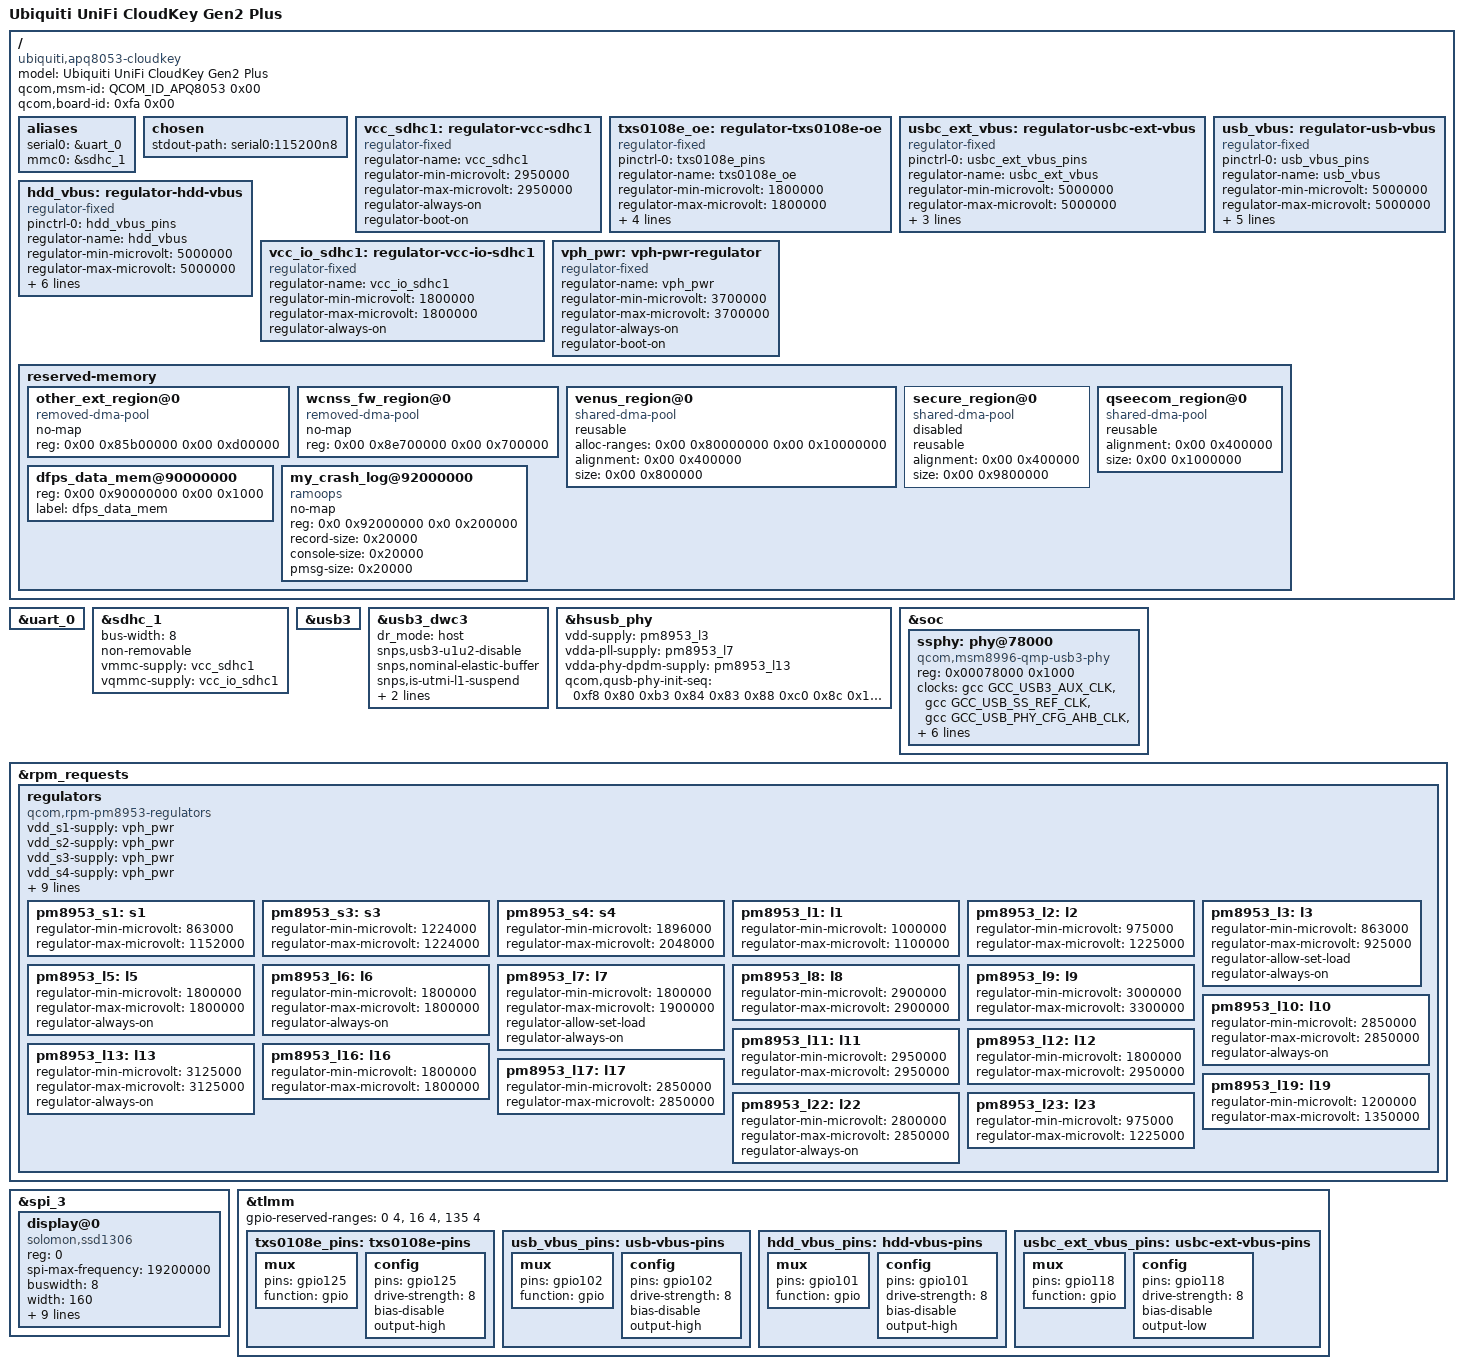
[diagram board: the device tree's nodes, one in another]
// SPDX-License-Identifier: BSD-3-Clause
/dts-v1/;

#include <dt-bindings/arm/qcom,ids.h>
#include "msm8953.dtsi"
#include "pm8953.dtsi"
#include <dt-bindings/gpio/gpio.h>

/ {
	model = "Ubiquiti UniFi CloudKey Gen2 Plus";
	compatible = "ubiquiti,apq8053-cloudkey", "qcom,apq8053-mtp", "qcom,apq8053", "qcom,mtp";
	qcom,msm-id = <QCOM_ID_APQ8053 0x00>;
	qcom,board-id = <0xfa 0x00>;

	aliases {
		serial0 = &uart_0;
		mmc0 = &sdhc_1; /* eMMC */
	};

	chosen {
		stdout-path = "serial0:115200n8";
	};

	/* Fixed regulators for eMMC and USB */
	vcc_sdhc1: regulator-vcc-sdhc1 {
		compatible = "regulator-fixed";
		regulator-name = "vcc_sdhc1";
		regulator-min-microvolt = <2950000>;
		regulator-max-microvolt = <2950000>;
		regulator-always-on;
		regulator-boot-on;
	};

	txs0108e_oe: regulator-txs0108e-oe {
		compatible = "regulator-fixed";
		pinctrl-names = "default";
		pinctrl-0 = <&txs0108e_pins>;
		regulator-name = "txs0108e_oe";
		regulator-min-microvolt = <1800000>;
		regulator-max-microvolt = <1800000>;
		startup-delay-us = <200>;
		gpio = <&tlmm 125 GPIO_ACTIVE_HIGH>;
		enable-active-high;
		regulator-always-on;
	};

	usbc_ext_vbus: regulator-usbc-ext-vbus {
		compatible = "regulator-fixed";
		pinctrl-names = "default";
		pinctrl-0 = <&usbc_ext_vbus_pins>;
		regulator-name = "usbc_ext_vbus";
		regulator-min-microvolt = <5000000>;
		regulator-max-microvolt = <5000000>;
		gpio = <&tlmm 118 GPIO_ACTIVE_LOW>;
		enable-active-low;
		regulator-always-on;
	};

	usb_vbus: regulator-usb-vbus {
		compatible = "regulator-fixed";
		pinctrl-names = "default";
		pinctrl-0 = <&usb_vbus_pins>;
		regulator-name = "usb_vbus";
		regulator-min-microvolt = <5000000>;
		regulator-max-microvolt = <5000000>;
		gpio = <&tlmm 102 GPIO_ACTIVE_HIGH>;
		enable-active-high;
		regulator-always-on;
		disable-on-shutdown;
		vin-supply = <&txs0108e_oe>;
	};

	hdd_vbus: regulator-hdd-vbus {
		compatible = "regulator-fixed";
		pinctrl-names = "default";
		pinctrl-0 = <&hdd_vbus_pins>;
		regulator-name = "hdd_vbus";
		regulator-min-microvolt = <5000000>;
		regulator-max-microvolt = <5000000>;
		startup-delay-us = <8000000>;
		gpio = <&tlmm 101 GPIO_ACTIVE_HIGH>;
		enable-active-high;
		regulator-always-on;
		disable-on-shutdown;
		vin-supply = <&txs0108e_oe>;
	};

	vcc_io_sdhc1: regulator-vcc-io-sdhc1 {
		compatible = "regulator-fixed";
		regulator-name = "vcc_io_sdhc1";
		regulator-min-microvolt = <1800000>;
		regulator-max-microvolt = <1800000>;
		regulator-always-on;
	};

	vph_pwr: vph-pwr-regulator {
		compatible = "regulator-fixed";
		regulator-name = "vph_pwr";
		regulator-min-microvolt = <3700000>;
		regulator-max-microvolt = <3700000>;
		regulator-always-on;
		regulator-boot-on;
	};

	reserved-memory {
		#address-cells = <2>;
		#size-cells = <2>;
		ranges;

		other_ext_region@0 {
			compatible = "removed-dma-pool";
			no-map;
			reg = <0x00 0x85b00000 0x00 0xd00000>;
		};

		wcnss_fw_region@0 {
			compatible = "removed-dma-pool";
			no-map;
			reg = <0x00 0x8e700000 0x00 0x700000>;
		};

		venus_region@0 {
			compatible = "shared-dma-pool";
			reusable;
			alloc-ranges = <0x00 0x80000000 0x00 0x10000000>;
			alignment = <0x00 0x400000>;
			size = <0x00 0x800000>;
		};

		secure_region@0 {
			compatible = "shared-dma-pool";
			reusable;
			alignment = <0x00 0x400000>;
			size = <0x00 0x9800000>;
			status = "disabled";
		};

		qseecom_region@0 {
			compatible = "shared-dma-pool";
			reusable;
			alignment = <0x00 0x400000>;
			size = <0x00 0x1000000>;
		};

		dfps_data_mem@90000000 {
			reg = <0x00 0x90000000 0x00 0x1000>;
			label = "dfps_data_mem";
		};

		my_crash_log@92000000 {
			compatible = "ramoops";
			no-map;
			reg = <0x0 0x92000000 0x0 0x200000>;
			record-size = <0x20000>;
			console-size = <0x20000>;
			pmsg-size = <0x20000>;
		};
	};
};

&uart_0 {
	status = "okay";
};

&sdhc_1 {
	status = "okay";
	bus-width = <8>;
	non-removable;
	vmmc-supply = <&vcc_sdhc1>;
	vqmmc-supply = <&vcc_io_sdhc1>;
};

&usb3 {
	status = "okay";
};

&usb3_dwc3 {
	dr_mode = "host";
	snps,usb3-u1u2-disable;
	snps,nominal-elastic-buffer;
	snps,is-utmi-l1-suspend;
	snps,hird-threshold = [00];
	phys = <&hsusb_phy>, <&ssphy>;
	phy-names = "usb2-phy", "usb3-phy";
};

&hsusb_phy {
	vdd-supply = <&pm8953_l3>;
	vdda-pll-supply = <&pm8953_l7>;
	vdda-phy-dpdm-supply = <&pm8953_l13>;
	qcom,qusb-phy-init-seq = <0xf8 0x80 0xb3 0x84 0x83 0x88 0xc0 0x8c 0x14 0x9c 0x30 0x08 0x79 0x0c 0x21 0x10 0x00 0x90 0x9f 0x1c 0x00 0x18>;
	status = "okay";
};

&soc {
	ssphy: phy@78000 {
		compatible = "qcom,msm8996-qmp-usb3-phy";
		reg = <0x00078000 0x1000>;
		clocks = <&gcc GCC_USB3_AUX_CLK>,
			 <&gcc GCC_USB_SS_REF_CLK>,
			 <&gcc GCC_USB_PHY_CFG_AHB_CLK>,
			 <&gcc GCC_USB3_PIPE_CLK>;
		clock-names = "aux", "ref", "cfg_ahb", "pipe";
		clock-output-names = "usb3_phy_pipe_clk_src";
		#clock-cells = <0>;
		#phy-cells = <0>;
		resets = <&gcc GCC_USB3_PHY_BCR>,
			 <&gcc GCC_USB3PHY_PHY_BCR>;
		reset-names = "phy", "phy_phy";
		vdda-phy-supply = <&pm8953_l3>;
		vdda-pll-supply = <&pm8953_l7>;
		status = "okay";
	};
};

&rpm_requests {
	regulators {
		compatible = "qcom,rpm-pm8953-regulators";

		vdd_s1-supply = <&vph_pwr>;
		vdd_s2-supply = <&vph_pwr>;
		vdd_s3-supply = <&vph_pwr>;
		vdd_s4-supply = <&vph_pwr>;
		vdd_s5-supply = <&vph_pwr>;
		vdd_s6-supply = <&vph_pwr>;
		vdd_s7-supply = <&vph_pwr>;
		vdd_l1-supply = <&pm8953_s3>;
		vdd_l2_l3-supply = <&pm8953_s3>;
		vdd_l4_l5_l6_l7_l16_l19-supply = <&pm8953_s4>;
		vdd_l8_l11_l12_l13_l14_l15-supply = <&vph_pwr>;
		vdd_l9_l10_l17_l18_l22-supply = <&vph_pwr>;
		vdd_l23-supply = <&pm8953_s3>;

		pm8953_s1: s1 {
			regulator-min-microvolt = <863000>;
			regulator-max-microvolt = <1152000>;
		};

		pm8953_s3: s3 {
			regulator-min-microvolt = <1224000>;
			regulator-max-microvolt = <1224000>;
		};

		pm8953_s4: s4 {
			regulator-min-microvolt = <1896000>;
			regulator-max-microvolt = <2048000>;
		};

		pm8953_l1: l1 {
			regulator-min-microvolt = <1000000>;
			regulator-max-microvolt = <1100000>;
		};

		pm8953_l2: l2 {
			regulator-min-microvolt = <975000>;
			regulator-max-microvolt = <1225000>;
		};

		pm8953_l3: l3 {
			regulator-min-microvolt = <863000>;
			regulator-max-microvolt = <925000>;
			regulator-allow-set-load;
			regulator-always-on;
		};

		pm8953_l5: l5 {
			regulator-min-microvolt = <1800000>;
			regulator-max-microvolt = <1800000>;
			regulator-always-on;
		};

		pm8953_l6: l6 {
			regulator-min-microvolt = <1800000>;
			regulator-max-microvolt = <1800000>;
			regulator-always-on;
		};

		pm8953_l7: l7 {
			regulator-min-microvolt = <1800000>;
			regulator-max-microvolt = <1900000>;
			regulator-allow-set-load;
			regulator-always-on;
		};

		pm8953_l8: l8 {
			regulator-min-microvolt = <2900000>;
			regulator-max-microvolt = <2900000>;
		};

		pm8953_l9: l9 {
			regulator-min-microvolt = <3000000>;
			regulator-max-microvolt = <3300000>;
		};

		pm8953_l10: l10 {
			regulator-min-microvolt = <2850000>;
			regulator-max-microvolt = <2850000>;
			regulator-always-on;
		};

		pm8953_l11: l11 {
			regulator-min-microvolt = <2950000>;
			regulator-max-microvolt = <2950000>;
		};

		pm8953_l12: l12 {
			regulator-min-microvolt = <1800000>;
			regulator-max-microvolt = <2950000>;
		};

		pm8953_l13: l13 {
			regulator-min-microvolt = <3125000>;
			regulator-max-microvolt = <3125000>;
			regulator-always-on;
		};

		pm8953_l16: l16 {
			regulator-min-microvolt = <1800000>;
			regulator-max-microvolt = <1800000>;
		};

		pm8953_l17: l17 {
			regulator-min-microvolt = <2850000>;
			regulator-max-microvolt = <2850000>;
		};

		pm8953_l19: l19 {
			regulator-min-microvolt = <1200000>;
			regulator-max-microvolt = <1350000>;
		};

		pm8953_l22: l22 {
			regulator-min-microvolt = <2800000>;
			regulator-max-microvolt = <2850000>;
			regulator-always-on;
		};

		pm8953_l23: l23 {
			regulator-min-microvolt = <975000>;
			regulator-max-microvolt = <1225000>;
		};
	};
};

&spi_3 {
	status = "okay";

	display@0 {
		compatible = "solomon,ssd1306";
		reg = <0>;
		spi-max-frequency = <19200000>;
		buswidth = <8>;
		width = <160>;
		height = <60>;
		solomon,width = <160>;
		solomon,height = <60>;
		reset-gpios = <&tlmm 35 GPIO_ACTIVE_LOW>;
		dc-gpios = <&tlmm 87 GPIO_ACTIVE_HIGH>;
		spi-cpha;
		spi-cpol;
		init = <0x1000001 0x2000096 0x1000011 0x20001F4 0x10000B1 0x01 0x2C 0x2D 0x10000B2 0x01 0x2C 0x2D 0x10000B3 0x01 0x2C 0x2D 0x01 0x2C 0x2D 0x10000B4 0x07 0x10000C0 0xA2 0x02 0x84 0x10000C1 0xC5 0x10000C2 0x0A 0x00 0x10000C3 0x8A 0x2A 0x10000C4 0x8A 0xEE 0x10000C5 0x0E 0x1000020 0x100003A 0x05 0x1000029 0x2000064 0x1000013 0x200000A>;
	};
};

&tlmm {
	gpio-reserved-ranges = <0 4>, <16 4>, <135 4>;

	txs0108e_pins: txs0108e-pins {
		mux {
			pins = "gpio125";
			function = "gpio";
		};
		config {
			pins = "gpio125";
			drive-strength = <8>;
			bias-disable;
			output-high;
		};
	};

	usb_vbus_pins: usb-vbus-pins {
		mux {
			pins = "gpio102";
			function = "gpio";
		};
		config {
			pins = "gpio102";
			drive-strength = <8>;
			bias-disable;
			output-high;
		};
	};

	hdd_vbus_pins: hdd-vbus-pins {
		mux {
			pins = "gpio101";
			function = "gpio";
		};
		config {
			pins = "gpio101";
			drive-strength = <8>;
			bias-disable;
			output-high;
		};
	};

	usbc_ext_vbus_pins: usbc-ext-vbus-pins {
		mux {
			pins = "gpio118";
			function = "gpio";
		};
		config {
			pins = "gpio118";
			drive-strength = <8>;
			bias-disable;
			output-low;
		};
	};
};
